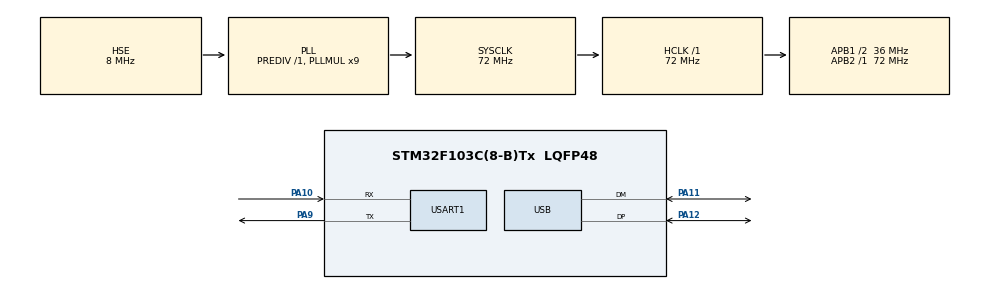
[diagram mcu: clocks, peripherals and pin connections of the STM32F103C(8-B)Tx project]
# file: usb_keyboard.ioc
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Mcu.Family=STM32F1
Mcu.Name=STM32F103C(8-B)Tx
Mcu.Package=LQFP48
NVIC.PriorityGroup=NVIC_PRIORITYGROUP_4
NVIC.USART1_IRQn=true\:1\:0\:true\:false\:true\:true\:true\:true
NVIC.USB_LP_CAN1_RX0_IRQn=true\:0\:0\:false\:false\:true\:false\:true\:true
PA10.Mode=Asynchronous
PA10.Signal=USART1_RX
PA11.Mode=Device
PA11.Signal=USB_DM
PA12.Mode=Device
PA12.Signal=USB_DP
PA13.Mode=Serial_Wire
PA13.Signal=SYS_JTMS-SWDIO
PA14.Mode=Serial_Wire
PA14.Signal=SYS_JTCK-SWCLK
PA9.Mode=Asynchronous
PA9.Signal=USART1_TX
PD0-OSC_IN.Mode=HSE-External-Oscillator
PD0-OSC_IN.Signal=RCC_OSC_IN
PD1-OSC_OUT.Mode=HSE-External-Oscillator
PD1-OSC_OUT.Signal=RCC_OSC_OUT
ProjectManager.HeapSize=0x200
ProjectManager.StackSize=0x400
ProjectManager.TargetToolchain=MDK-ARM V5
RCC.AHBFreq_Value=72000000
RCC.APB1CLKDivider=RCC_HCLK_DIV2
RCC.APB1Freq_Value=36000000
RCC.APB1TimFreq_Value=72000000
RCC.APB2Freq_Value=72000000
RCC.APB2TimFreq_Value=72000000
RCC.HCLKFreq_Value=72000000
RCC.PLLMUL=RCC_PLL_MUL9
RCC.SYSCLKFreq_VALUE=72000000
RCC.SYSCLKSource=RCC_SYSCLKSOURCE_PLLCLK
RCC.USBFreq_Value=48000000
RCC.USBPrescaler=RCC_USBCLKSOURCE_PLL_DIV1_5
USART1.VirtualMode=VM_ASYNC
USB_DEVICE.CLASS_NAME_FS=HID
USB_DEVICE.VirtualMode=Hid
USB_DEVICE.VirtualModeFS=Hid_FS
VP_USB_DEVICE_VS_USB_DEVICE_HID_FS.Mode=HID_FS
board=custom

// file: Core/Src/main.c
/* USER CODE BEGIN Header */
/**
  ******************************************************************************
  * @file           : main.c
  * @brief          : Main program body
  ******************************************************************************
  * @attention
  *
  * Copyright (c) 2025 STMicroelectronics.
  * All rights reserved.
  *
  * This software is licensed under terms that can be found in the LICENSE file
  * in the root directory of this software component.
  * If no LICENSE file comes with this software, it is provided AS-IS.
  *
  ******************************************************************************
  */
/* USER CODE END Header */
#include "main.h"
#include "usart.h"
#include "usb_device.h"
#include "gpio.h"

/* USER CODE BEGIN PM */
extern USBD_HandleTypeDef hUsbDeviceFS;
//存放包头的数据包
uint8_t Keyboard[9] = {0, 0, 0, 0, 0, 0, 0, 0, 0};
//去除包头的数据包
uint8_t NewKeyboard[8];
void HAL_UART_RxCpltCallback(UART_HandleTypeDef *huart)
{

	//继续接收
	HAL_UART_Receive_IT(&huart1,Keyboard, sizeof(Keyboard));
	//判断数据包的包头是否为正确数据,避免数据处理出错
	if(Keyboard[0] == 0x0a)
	{

		// 从下标1开始复制元素到新的数组，去掉标头,形成一个新数组，符合usb-hid的鼠标规范
    for (int i = 0; i < 8; i++) {
        NewKeyboard[i] = Keyboard[i + 1];
    }
		//执行鼠标指令
		USBD_HID_SendReport(&hUsbDeviceFS,(uint8_t*)NewKeyboard,sizeof(NewKeyboard));
		//把接收到的数据传送回去
		HAL_UART_Transmit_IT(&huart1,NewKeyboard, sizeof(NewKeyboard));
	}

}
/* USER CODE END PM */

void SystemClock_Config(void);

int main(void)
{

  /* MCU Configuration--------------------------------------------------------*/

  /* Reset of all peripherals, Initializes the Flash interface and the Systick. */
  HAL_Init();

  /* Configure the system clock */
  SystemClock_Config();

  /* Initialize all configured peripherals */
  MX_GPIO_Init();
  MX_USART1_UART_Init();
  MX_USB_DEVICE_Init();

  /* Infinite loop */
  /* USER CODE BEGIN WHILE */
	HAL_UART_Receive_IT(&huart1,Keyboard,sizeof(Keyboard));
  while (1)
  {

    /* USER CODE END WHILE */

  }
}

void SystemClock_Config(void)
{
  RCC_OscInitTypeDef RCC_OscInitStruct = {0};
  RCC_ClkInitTypeDef RCC_ClkInitStruct = {0};
  RCC_PeriphCLKInitTypeDef PeriphClkInit = {0};

  /** Initializes the RCC Oscillators according to the specified parameters
  * in the RCC_OscInitTypeDef structure.
  */
  RCC_OscInitStruct.OscillatorType = RCC_OSCILLATORTYPE_HSE;
  RCC_OscInitStruct.HSEState = RCC_HSE_ON;
  RCC_OscInitStruct.HSEPredivValue = RCC_HSE_PREDIV_DIV1;
  RCC_OscInitStruct.HSIState = RCC_HSI_ON;
  RCC_OscInitStruct.PLL.PLLState = RCC_PLL_ON;
  RCC_OscInitStruct.PLL.PLLSource = RCC_PLLSOURCE_HSE;
  RCC_OscInitStruct.PLL.PLLMUL = RCC_PLL_MUL9;
  if (HAL_RCC_OscConfig(&RCC_OscInitStruct) != HAL_OK)
  {
    Error_Handler();
  }

  /** Initializes the CPU, AHB and APB buses clocks
  */
  RCC_ClkInitStruct.ClockType = RCC_CLOCKTYPE_HCLK|RCC_CLOCKTYPE_SYSCLK
                              |RCC_CLOCKTYPE_PCLK1|RCC_CLOCKTYPE_PCLK2;
  RCC_ClkInitStruct.SYSCLKSource = RCC_SYSCLKSOURCE_PLLCLK;
  RCC_ClkInitStruct.AHBCLKDivider = RCC_SYSCLK_DIV1;
  RCC_ClkInitStruct.APB1CLKDivider = RCC_HCLK_DIV2;
  RCC_ClkInitStruct.APB2CLKDivider = RCC_HCLK_DIV1;

  if (HAL_RCC_ClockConfig(&RCC_ClkInitStruct, FLASH_LATENCY_2) != HAL_OK)
  {
    Error_Handler();
  }
  PeriphClkInit.PeriphClockSelection = RCC_PERIPHCLK_USB;
  PeriphClkInit.UsbClockSelection = RCC_USBCLKSOURCE_PLL_DIV1_5;
  if (HAL_RCCEx_PeriphCLKConfig(&PeriphClkInit) != HAL_OK)
  {
    Error_Handler();
  }
}

void Error_Handler(void)
{
  __disable_irq();
  while (1)
  {
  }
}
